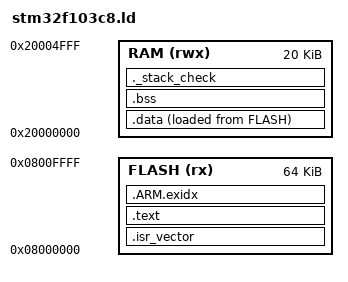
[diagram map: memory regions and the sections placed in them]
/* Linker script for the STM32F103C8: 64 KB flash, 20 KB RAM */

ENTRY(Reset_Handler)

MEMORY
{
    FLASH (rx)  : ORIGIN = 0x08000000, LENGTH = 64K
    RAM   (rwx) : ORIGIN = 0x20000000, LENGTH = 20K
}

_estack = ORIGIN(RAM) + LENGTH(RAM);   /* the stack starts at the top of RAM */
_min_stack = 0x800;                    /* 2 KB kept free for the stack (checked below) */

SECTIONS
{
    .isr_vector : { KEEP(*(.isr_vector)) } > FLASH

    .text :
    {
        *(.text*)
        *(.rodata*)
        . = ALIGN(4);
    } > FLASH

    .ARM.exidx : { *(.ARM.exidx*) } > FLASH

    _sidata = LOADADDR(.data);
    .data :
    {
        . = ALIGN(4);
        _sdata = .;
        *(.data*)
        . = ALIGN(4);
        _edata = .;
    } > RAM AT > FLASH

    .bss (NOLOAD) :
    {
        . = ALIGN(4);
        _sbss = .;
        *(.bss*)
        *(COMMON)
        . = ALIGN(4);
        _ebss = .;
    } > RAM

    end = _ebss;                           /* used by newlib if it ever needs a heap */

    ._stack_check (NOLOAD) :
    {
        . = . + _min_stack;
    } > RAM
}
